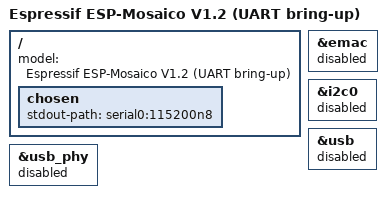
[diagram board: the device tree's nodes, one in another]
// SPDX-License-Identifier: (GPL-2.0 OR MIT)
#include "esp32s31.dts"

/ {
    model = "Espressif ESP-Mosaico V1.2 (UART bring-up)";

    chosen {
        stdout-path = "serial0:115200n8";
    };
};

&emac {
    status = "disabled";
};

&i2c0 {
    status = "disabled";
};

&usb {
    status = "disabled";
};

&usb_phy {
    status = "disabled";
};
